# PY32T020xx register map
Vendor: Puya; Series: PY32L0; File version: 1.0.0
CPU: CM0+ r0p1, little endian, no MPU, no FPU, 4 interrupt priority bits
Registers are 32-bit, read-write, reset 0x0 unless marked. A register's access mark holds for its fields unless they carry their own. Offsets are from the block's base; [hi:lo] are bit positions; {n}, {i} and the like mark numbered series.

## COMP1 — Comparator 1
Base 0x40010200
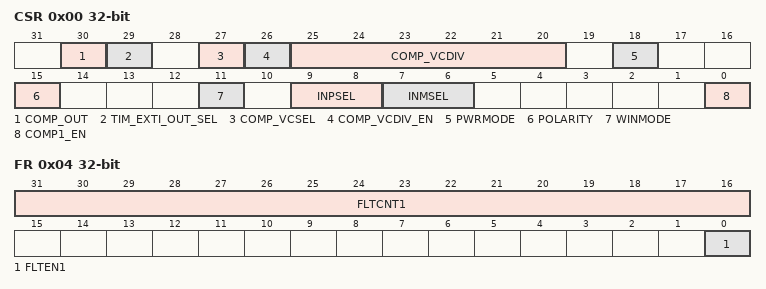
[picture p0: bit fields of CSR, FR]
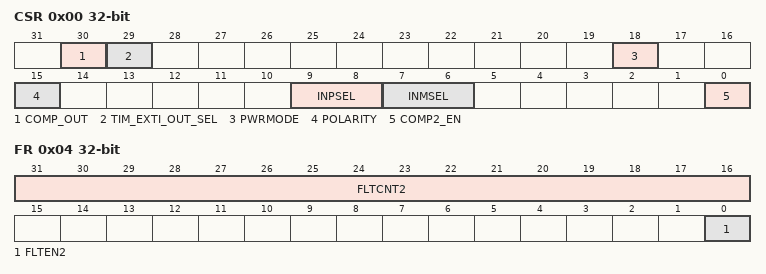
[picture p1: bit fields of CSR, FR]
0x00 CSR — COMP control and status register
  [30] COMP_OUT ro — COMP1 output status
  [29] TIM_EXTI_OUT_SEL — COMP1 output to TIM/EXTI selection
  [27] COMP_VCSEL — VREFCMP reference source selection
  [26] COMP_VCDIV_EN — VREFCMP voltage divider enable signal
  [25:20] COMP_VCDIV — COMP1, COMP2 partial voltage selection
    1=0; 2=1; 4=2; 8=3; 16=4; 32=5
  [18] PWRMODE — COMP1 power mode selection
  [15] POLARITY — COMP1 output polarity selection
  [11] WINMODE — COMP1 window mode enable
  [9:8] INPSEL — COMP1 positive input select
    1=0; 2=1
  [7:6] INMSEL — COMP1 negative input select
    1=0; 2=1
  [0] COMP1_EN — COMP1 enable bit
0x04 FR — Comparator Filter register
  [31:16] FLTCNT1 — Comparator 1 sampling filter counter
  [0] FLTEN1 — Comparator 1 digital filter configuration

## COMP2 — Comparator2
Base 0x40010210
0x00 CSR — COMP control and status register
  [30] COMP_OUT ro — COMP2 output status
  [29] TIM_EXTI_OUT_SEL — COMP2 output to TIM/EXTI selection
  [18] PWRMODE — COMP2 power mode selection
  [15] POLARITY — COMP2 output polarity selection
  [9:8] INPSEL — COMP2 positive input select
    1=0; 2=1
  [7:6] INMSEL — COMP2 negative input select
    1=0; 2=1
  [0] COMP2_EN — COMP2 enable bit
0x04 FR — Comparator Filter register
  [31:16] FLTCNT2 — Comparator 2 sampling filter counter
  [0] FLTEN2 — Comparator 2 digital filtering configuration

## CRC — CRC calculation unit
Base 0x40023000
0x00 DR — Data register
  [31:0] DR — Data register bits
0x04 IDR — Independent Data register
  [7:0] IDR — General-purpose 8-bit data register bits
0x08 CR — Control register
  [0] RESET wo — Reset the CRC module

## DBGMCU — Debug support
Base 0x40015800
0x00 IDCODE ro — MCU Device ID Code Register
  [31:0] REV_ID
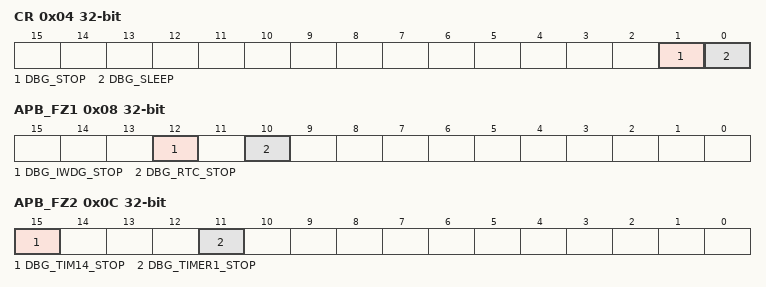
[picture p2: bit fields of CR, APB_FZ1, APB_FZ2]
0x04 CR — Debug MCU Configuration Register
  [1] DBG_STOP — Debug Stop Mode
  [0] DBG_SLEEP — Debug Sleep Mode
0x08 APB_FZ1 — APB Freeze Register1
  [12] DBG_IWDG_STOP — Debug Independent Wachdog stopped whenCore is halted
  [10] DBG_RTC_STOP — Debug RTC stopped whenCore is halted
0x0C APB_FZ2 — APB Freeze Register2
  [15] DBG_TIM14_STOP — Debug TIM 14 stopped whenCore is halted
  [11] DBG_TIMER1_STOP — Debug Timer 1 stopped when Core ishalted

## EXTI — External interrupt/event controller
Base 0x40021800
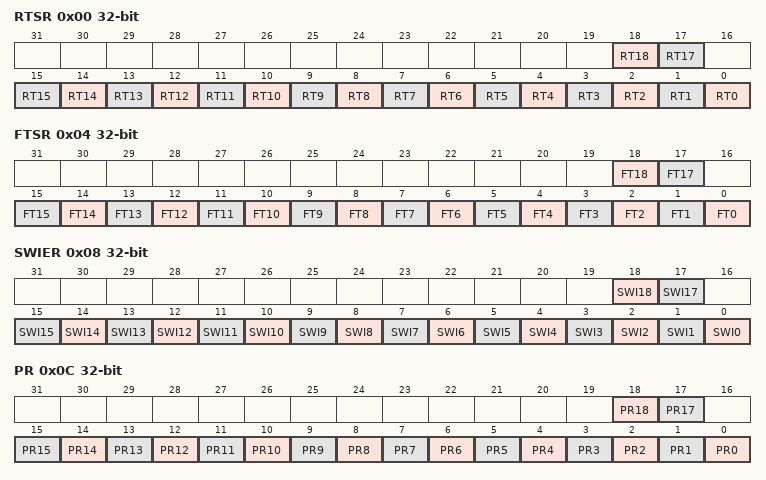
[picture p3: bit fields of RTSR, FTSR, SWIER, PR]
0x00 RTSR — EXTI rising trigger selection register
  [18] RT18 — Rising trigger event configuration bit of Configurable Event input
  [17] RT17 — Rising trigger event configuration bit of Configurable Event input
  [n] RT{n} (n=0..15) — Rising trigger event configuration bit of Configurable Event input
0x04 FTSR — EXTI falling trigger selection register
  [18] FT18 — Falling trigger event configuration bit of Configurable Event input
  [17] FT17 — Falling trigger event configuration bit of Configurable Event input
  [n] FT{n} (n=0..15) — Falling trigger event configuration bit of Configurable Event input
0x08 SWIER — EXTI software interrupt event register
  [18] SWI18 — Configurable exti linex enable of soft trigle
  [17] SWI17 — Configurable exti linex enable of soft trigle
  [n] SWI{n} (n=0..15) — Configurable exti linex enable of soft trigle
0x0C PR — EXTI pending register
  [18] PR18 — Pending line of exti
  [17] PR17 — Pending line of exti
  [n] PR{n} (n=0..15) — Pending line of exti
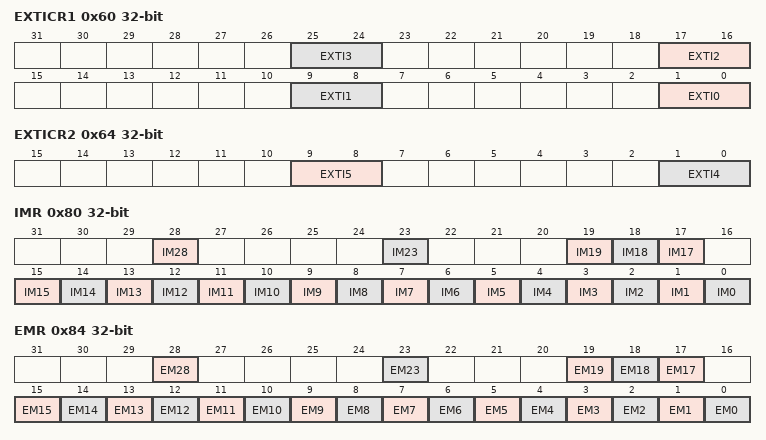
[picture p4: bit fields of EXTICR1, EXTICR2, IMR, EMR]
0x60 EXTICR1
  [all] fields
    1=0; 2=1
  [8n+1:8n] EXTI{n} (n=0..3) — GPIO exti line select
0x64 EXTICR2
  [9:8] EXTI5 — GPIO exti line select
    1=0; 2=1
  [1:0] EXTI4 — GPIO exti line select
    1=0; 2=1
0x80 IMR — EXTI CPU wakeup with interrupt mask register
  [28] IM28 — EXIT Mask enable
  [23] IM23 — EXIT Mask enable
  [19] IM19 — EXIT Mask enable
  [18] IM18 — EXIT Mask enable
  [17] IM17 — EXIT Mask enable
  [n] IM{n} (n=0..15) — EXIT Mask enable
0x84 EMR — EXTI CPU wakeup with event mask register
  [28] EM28 — EXIT Mask enable
  [23] EM23 — EXIT Mask enable
  [19] EM19 — EXIT Mask enable
  [18] EM18 — EXIT Mask enable
  [17] EM17 — EXIT Mask enable
  [n] EM{n} (n=0..15) — EXIT Mask enable
